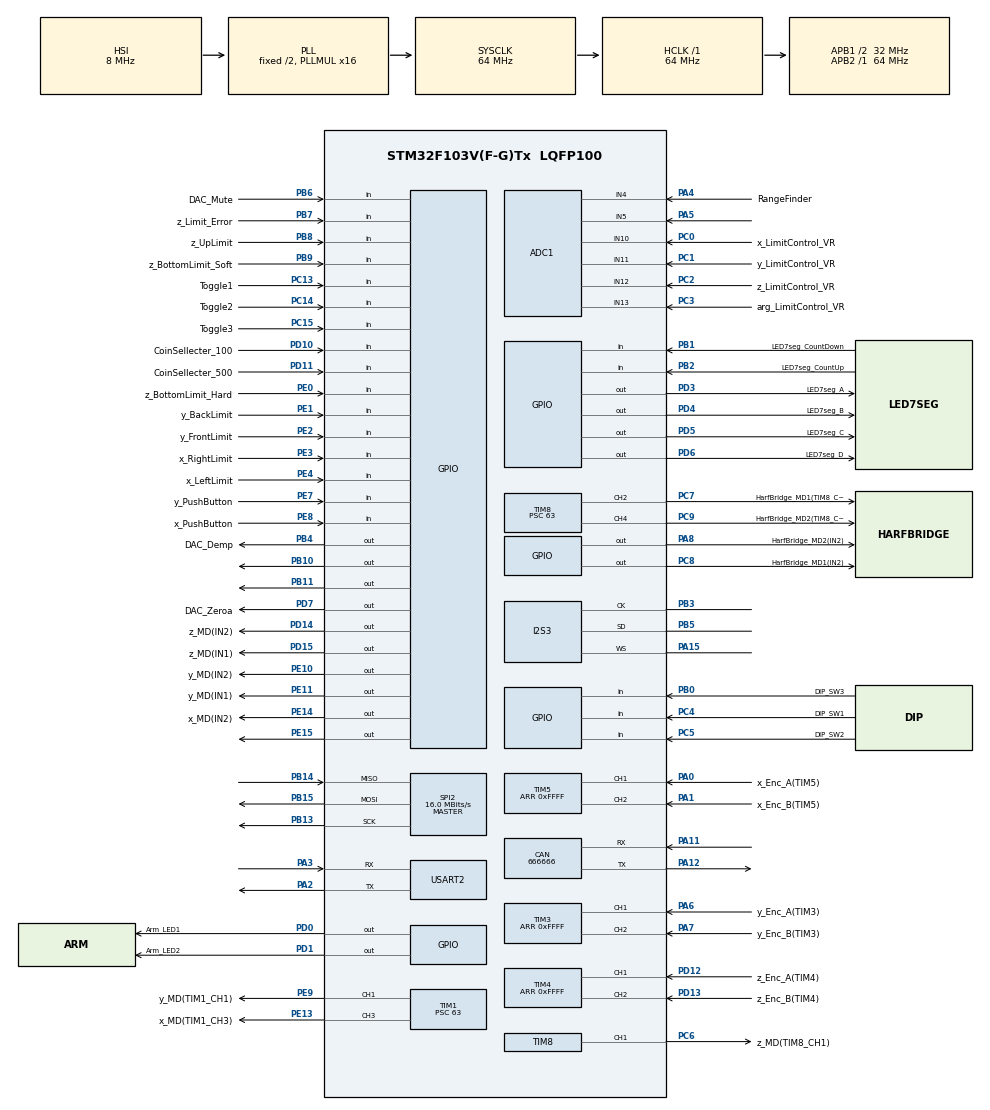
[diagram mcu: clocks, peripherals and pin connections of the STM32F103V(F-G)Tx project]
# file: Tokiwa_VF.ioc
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ADC1.Channel-0\#ChannelRegularConversion=ADC_CHANNEL_10
ADC1.Channel-1\#ChannelRegularConversion=ADC_CHANNEL_11
ADC1.Channel-2\#ChannelRegularConversion=ADC_CHANNEL_12
ADC1.Channel-3\#ChannelRegularConversion=ADC_CHANNEL_13
ADC1.Channel-4\#ChannelRegularConversion=ADC_CHANNEL_5
ADC1.Channel-5\#ChannelRegularConversion=ADC_CHANNEL_4
ADC1.ContinuousConvMode=ENABLE
ADC1.NbrOfConversion=6
ADC1.NbrOfConversionFlag=1
ADC1.Rank-0\#ChannelRegularConversion=1
ADC1.Rank-1\#ChannelRegularConversion=2
ADC1.Rank-2\#ChannelRegularConversion=3
ADC1.Rank-3\#ChannelRegularConversion=4
ADC1.Rank-4\#ChannelRegularConversion=5
ADC1.Rank-5\#ChannelRegularConversion=6
ADC1.SamplingTime-0\#ChannelRegularConversion=ADC_SAMPLETIME_13CYCLES_5
ADC1.SamplingTime-1\#ChannelRegularConversion=ADC_SAMPLETIME_13CYCLES_5
ADC1.SamplingTime-2\#ChannelRegularConversion=ADC_SAMPLETIME_13CYCLES_5
ADC1.SamplingTime-3\#ChannelRegularConversion=ADC_SAMPLETIME_13CYCLES_5
ADC1.SamplingTime-4\#ChannelRegularConversion=ADC_SAMPLETIME_13CYCLES_5
ADC1.SamplingTime-5\#ChannelRegularConversion=ADC_SAMPLETIME_13CYCLES_5
ADC1.master=1
CAN.BS1=CAN_BS1_1TQ
CAN.BS2=CAN_BS2_1TQ
CAN.CalculateBaudRate=666666
CAN.CalculateTimeBit=1500.00
CAN.CalculateTimeQuantum=500.0
Dma.ADC1.0.Direction=DMA_PERIPH_TO_MEMORY
Dma.ADC1.0.Instance=DMA1_Channel1
Dma.ADC1.0.MemDataAlignment=DMA_MDATAALIGN_HALFWORD
Dma.ADC1.0.MemInc=DMA_MINC_ENABLE
Dma.ADC1.0.Mode=DMA_CIRCULAR
Dma.ADC1.0.PeriphDataAlignment=DMA_PDATAALIGN_HALFWORD
Dma.ADC1.0.PeriphInc=DMA_PINC_DISABLE
Dma.ADC1.0.Priority=DMA_PRIORITY_LOW
Dma.Request0=ADC1
I2S3.ErrorAudioFreq=0.0 %
I2S3.Instance=SPI$Index
I2S3.RealAudioFreq=8.0 KHz
I2S3.VirtualMode=I2S_MODE_MASTER
Mcu.Family=STM32F1
Mcu.Name=STM32F103V(F-G)Tx
Mcu.Package=LQFP100
NVIC.DMA1_Channel1_IRQn=true\:0\:0\:false\:false\:true\:false\:true
NVIC.PriorityGroup=NVIC_PRIORITYGROUP_4
NVIC.TIM6_IRQn=true\:1\:0\:true\:false\:true\:true\:true
PA0-WKUP.GPIO_Label=x_Enc_A(TIM5)
PA0-WKUP.Signal=S_TIM5_CH1
PA1.GPIO_Label=x_Enc_B(TIM5)
PA1.Signal=S_TIM5_CH2
PA10.Signal=USART1_RX
PA11.Mode=CAN_Activate
PA11.Signal=CAN_RX
PA12.Mode=CAN_Activate
PA12.Signal=CAN_TX
PA13.Signal=SYS_JTMS-SWDIO
PA14.Signal=SYS_JTCK-SWCLK
PA15.Mode=Half_Duplex_Master_TX
PA15.Signal=I2S3_WS
PA2.Mode=Asynchronous
PA2.Signal=USART2_TX
PA3.Mode=Asynchronous
PA3.Signal=USART2_RX
PA4.GPIO_Label=RangeFinder
PA4.Signal=ADCx_IN4
PA5.Signal=ADCx_IN5
PA6.GPIO_Label=y_Enc_A(TIM3)
PA6.Signal=S_TIM3_CH1
PA7.GPIO_Label=y_Enc_B(TIM3)
PA7.Signal=S_TIM3_CH2
PA8.GPIO_Label=HarfBridge_MD2(IN2)
PA8.Signal=GPIO_Output
PA9.Signal=USART1_TX
PB0.GPIO_Label=DIP_SW3
PB0.Signal=GPIO_Input
PB1.GPIO_Label=LED7seg_CountDown
PB1.Signal=GPIO_Input
PB10.GPIO_PuPd=GPIO_PULLDOWN
PB10.Signal=GPIO_Output
PB11.GPIO_PuPd=GPIO_PULLDOWN
PB11.Signal=GPIO_Output
PB13.Mode=Full_Duplex_Master
PB13.Signal=SPI2_SCK
PB14.Mode=Full_Duplex_Master
PB14.Signal=SPI2_MISO
PB15.Mode=Full_Duplex_Master
PB15.Signal=SPI2_MOSI
PB2.GPIO_Label=LED7seg_CountUp
PB2.Signal=GPIO_Input
PB3.Mode=Half_Duplex_Master_TX
PB3.Signal=I2S3_CK
PB4.GPIO_Label=DAC_Demp
PB4.Signal=GPIO_Output
PB5.Mode=Half_Duplex_Master_TX
PB5.Signal=I2S3_SD
PB6.GPIO_Label=DAC_Mute
PB6.Signal=GPIO_Input
PB7.GPIO_Label=z_Limit_Error
PB7.Signal=GPIO_Input
PB8.GPIO_Label=z_UpLimit
PB8.Signal=GPIO_Input
PB9.GPIO_Label=z_BottomLimit_Soft
PB9.Signal=GPIO_Input
PC0.GPIO_Label=x_LimitControl_VR
PC0.Signal=ADCx_IN10
PC1.GPIO_Label=y_LimitControl_VR
PC1.Signal=ADCx_IN11
PC10.Signal=UART4_TX
PC11.Signal=UART4_RX
PC12.Signal=UART5_TX
PC13-TAMPER-RTC.GPIO_Label=Toggle1
PC13-TAMPER-RTC.Signal=GPIO_Input
PC14-OSC32_IN.GPIO_Label=Toggle2
PC14-OSC32_IN.Signal=GPIO_Input
PC15-OSC32_OUT.GPIO_Label=Toggle3
PC15-OSC32_OUT.Signal=GPIO_Input
PC2.GPIO_Label=z_LimitControl_VR
PC2.Signal=ADCx_IN12
PC3.GPIO_Label=arg_LimitControl_VR
PC3.Signal=ADCx_IN13
PC4.GPIO_Label=DIP_SW1
PC4.Signal=GPIO_Input
PC5.GPIO_Label=DIP_SW2
PC5.Signal=GPIO_Input
PC6.GPIO_Label=z_MD(TIM8_CH1)
PC6.Signal=S_TIM8_CH1
PC7.GPIO_Label=HarfBridge_MD1(TIM8_CH2)
PC7.Signal=S_TIM8_CH2
PC8.GPIO_Label=HarfBridge_MD1(IN2)
PC8.Signal=GPIO_Output
PC9.GPIO_Label=HarfBridge_MD2(TIM8_CH4)
PC9.Signal=S_TIM8_CH4
PD0.GPIO_Label=Arm_LED1
PD0.Signal=GPIO_Output
PD1.GPIO_Label=Arm_LED2
PD1.Signal=GPIO_Output
PD10.GPIO_Label=CoinSellecter_100
PD10.GPIO_PuPd=GPIO_PULLDOWN
PD10.Signal=GPIO_Input
PD11.GPIO_Label=CoinSellecter_500
PD11.Signal=GPIO_Input
PD12.GPIO_Label=z_Enc_A(TIM4)
PD12.Signal=S_TIM4_CH1
PD13.GPIO_Label=z_Enc_B(TIM4)
PD13.Signal=S_TIM4_CH2
PD14.GPIO_Label=z_MD(IN2)
PD14.Signal=GPIO_Output
PD15.GPIO_Label=z_MD(IN1)
PD15.Signal=GPIO_Output
PD2.Signal=UART5_RX
PD3.GPIO_Label=LED7seg_A
PD3.Signal=GPIO_Output
PD4.GPIO_Label=LED7seg_B
PD4.Signal=GPIO_Output
PD5.GPIO_Label=LED7seg_C
PD5.Signal=GPIO_Output
PD6.GPIO_Label=LED7seg_D
PD6.Signal=GPIO_Output
PD7.GPIO_Label=DAC_Zeroa
PD7.Signal=GPIO_Output
PD8.Signal=USART3_TX
PD9.Signal=USART3_RX
PE0.GPIO_Label=z_BottomLimit_Hard
PE0.Signal=GPIO_Input
PE1.GPIO_Label=y_BackLimit
PE1.Signal=GPIO_Input
PE10.GPIO_Label=y_MD(IN2)
PE10.Signal=GPIO_Output
PE11.GPIO_Label=y_MD(IN1)
PE11.Signal=GPIO_Output
PE13.GPIO_Label=x_MD(TIM1_CH3)
PE13.Signal=S_TIM1_CH3
PE14.GPIO_Label=x_MD(IN2)
PE14.Signal=GPIO_Output
PE15.Signal=GPIO_Output
PE2.GPIO_Label=y_FrontLimit
PE2.Signal=GPIO_Input
PE3.GPIO_Label=x_RightLimit
PE3.Signal=GPIO_Input
PE4.GPIO_Label=x_LeftLimit
PE4.Signal=GPIO_Input
PE5.Signal=S_TIM9_CH1
PE6.Signal=S_TIM9_CH2
PE7.GPIO_Label=y_PushButton
PE7.Signal=GPIO_Input
PE8.GPIO_Label=x_PushButton
PE8.Signal=GPIO_Input
PE9.GPIO_Label=y_MD(TIM1_CH1)
PE9.Signal=S_TIM1_CH1
ProjectManager.HeapSize=0x200
ProjectManager.StackSize=0x400
ProjectManager.TargetToolchain=STM32CubeIDE
RCC.ADCPresc=RCC_ADCPCLK2_DIV6
RCC.AHBFreq_Value=64000000
RCC.APB1CLKDivider=RCC_HCLK_DIV2
RCC.APB1Freq_Value=32000000
RCC.APB1TimFreq_Value=64000000
RCC.APB2Freq_Value=64000000
RCC.APB2TimFreq_Value=64000000
RCC.HCLKFreq_Value=64000000
RCC.PLLMUL=RCC_PLL_MUL16
RCC.SYSCLKFreq_VALUE=64000000
RCC.SYSCLKSource=RCC_SYSCLKSOURCE_PLLCLK
RCC.USBFreq_Value=64000000
SH.ADCx_IN10.0=ADC1_IN10,IN10
SH.ADCx_IN11.0=ADC1_IN11,IN11
SH.ADCx_IN12.0=ADC1_IN12,IN12
SH.ADCx_IN13.0=ADC1_IN13,IN13
SH.ADCx_IN4.0=ADC1_IN4,IN4
SH.ADCx_IN5.0=ADC1_IN5,IN5
SH.S_TIM1_CH1.0=TIM1_CH1,PWM Generation1 CH1
SH.S_TIM1_CH3.0=TIM1_CH3,PWM Generation3 CH3
SH.S_TIM3_CH1.0=TIM3_CH1,Encoder_Interface
SH.S_TIM3_CH2.0=TIM3_CH2,Encoder_Interface
SH.S_TIM4_CH1.0=TIM4_CH1,Encoder_Interface
SH.S_TIM4_CH2.0=TIM4_CH2,Encoder_Interface
SH.S_TIM5_CH1.0=TIM5_CH1,Encoder_Interface
SH.S_TIM5_CH2.0=TIM5_CH2,Encoder_Interface
SH.S_TIM8_CH1.0=TIM8_CH1,PWM Generation1 CH1
SH.S_TIM8_CH2.0=TIM8_CH2,PWM Generation2 CH2
SH.S_TIM8_CH4.0=TIM8_CH4,PWM Generation4 CH4
SH.S_TIM9_CH1.0=TIM9_CH1
SH.S_TIM9_CH2.0=TIM9_CH2
SPI2.BaudRatePrescaler=SPI_BAUDRATEPRESCALER_2
SPI2.CalculateBaudRate=16.0 MBits/s
SPI2.Direction=SPI_DIRECTION_2LINES
SPI2.Mode=SPI_MODE_MASTER
SPI2.VirtualType=VM_MASTER
TIM1.Channel-PWM\ Generation1\ CH1=TIM_CHANNEL_1
TIM1.Channel-PWM\ Generation3\ CH3=TIM_CHANNEL_3
TIM1.Period=99
TIM1.Prescaler=63
TIM2.Period=99
TIM2.Prescaler=31
TIM3.EncoderMode=TIM_ENCODERMODE_TI12
TIM3.IC1Prescaler=TIM_ICPSC_DIV1
TIM3.IC2Prescaler=TIM_ICPSC_DIV1
TIM3.Period=0xFFFF
TIM4.EncoderMode=TIM_ENCODERMODE_TI12
TIM4.Period=0xFFFF
TIM5.EncoderMode=TIM_ENCODERMODE_TI12
TIM5.Period=0xFFFF
TIM6.Period=99
TIM6.Prescaler=6399
TIM8.Channel-PWM\ Generation1\ CH1=TIM_CHANNEL_1
TIM8.Channel-PWM\ Generation2\ CH2=TIM_CHANNEL_2
TIM8.Channel-PWM\ Generation4\ CH4=TIM_CHANNEL_4
TIM8.Period=99
TIM8.Prescaler=63
USART2.VirtualMode=VM_ASYNC
VP_SYS_VS_ND.Mode=No_Debug
VP_TIM2_VS_OPM.Mode=OPM_bit
VP_TIM6_VS_ClockSourceINT.Mode=Enable_Timer
board=custom

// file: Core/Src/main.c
/* USER CODE BEGIN Header */
/**
  ******************************************************************************
  * @file           : main.c
  * @brief          : Main program body
  ******************************************************************************
  * @attention
  *
  * <h2><center>&copy; Copyright (c) 2019 STMicroelectronics.
  * All rights reserved.</center></h2>
  *
  * This software component is licensed by ST under BSD 3-Clause license,
  * the "License"; You may not use this file except in compliance with the
  * License. You may obtain a copy of the License at:
  *                        opensource.org/licenses/BSD-3-Clause
  *
  ******************************************************************************
  */
/* USER CODE END Header */
#include "main.h"
#include "adc.h"
#include "can.h"
#include "dma.h"
#include "i2s.h"
#include "spi.h"
#include "tim.h"
#include "usart.h"
#include "gpio.h"

/* USER CODE BEGIN Includes */
#include "buttons.h"
#include "limitswitches.h"
#include "toggleswitches.h"
#include "dipswitches.h"
#include "encoder.h"
#include "led7seg.h"
#include "motor.h"
#include <math.h>
#include <stdio.h>

/* USER CODE END Includes */

/* USER CODE BEGIN PM */
#define X_ENC_LIMIT (77680)
#define Y_ENC_LIMIT (58000) // マイナス
#define Z_ENC_LIMIT (160000) // マイナス

/* USER CODE END PM */

/* USER CODE BEGIN PV */
static uint16_t adcbuff[6]; // 0~2:xyzLimit 3:XY速度 4:開閉速度 6番目はRangeFinder
static uint8_t count = 0;
static int32_t x_enc = 0, y_enc = 0, z_enc = 0;
/* USER CODE END PV */

void SystemClock_Config(void);
/* USER CODE BEGIN PFP */
void Rot90deg_Stepper(float rpm);
void Update_Enc(void);
/* USER CODE END PFP */

int main(void)
{

  /* MCU Configuration--------------------------------------------------------*/

  /* Reset of all peripherals, Initializes the Flash interface and the Systick. */
  HAL_Init();

  /* Configure the system clock */
  SystemClock_Config();

  /* Initialize all configured peripherals */
  MX_GPIO_Init();
  MX_DMA_Init();
  MX_ADC1_Init();
  MX_CAN_Init();
  MX_I2S3_Init();
  MX_SPI2_Init();
  MX_TIM1_Init();
  MX_TIM2_Init();
  MX_TIM3_Init();
  MX_TIM4_Init();
  MX_TIM5_Init();
  MX_TIM8_Init();
  MX_USART2_UART_Init();
  MX_TIM6_Init();
  /* USER CODE BEGIN 2 */
  HAL_UART_Transmit(&huart2, "START\r\n", 7, 0xFFFF);
  HAL_TIM_Encoder_Start(&htim3, TIM_CHANNEL_ALL);
  HAL_TIM_Encoder_Start(&htim4, TIM_CHANNEL_ALL);
  HAL_TIM_Encoder_Start(&htim5, TIM_CHANNEL_ALL);

  HAL_GPIO_WritePin(Arm_LED1_GPIO_Port, Arm_LED1_Pin, GPIO_PIN_SET);
  HAL_GPIO_WritePin(Arm_LED2_GPIO_Port, Arm_LED2_Pin, GPIO_PIN_SET);

  HAL_TIM_PWM_Start(&htim1, TIM_CHANNEL_3);
  HAL_TIM_PWM_Start(&htim1, TIM_CHANNEL_1);
  HAL_TIM_PWM_Start(&htim8, TIM_CHANNEL_1);

  Display_led7seg(count);

  /* ADCサンプリング･DMA転送開始 */
  HAL_ADC_Start_DMA(&hadc1, adcbuff, 6);

//  while (1) {
//      uint8_t buff[40];
//      HAL_ADC_Start_DMA(&hadc1, adcbuff, 6);
//      sprintf(buff, "%4d %4d %4d %4d %4d %4d ", adcbuff[0], adcbuff[1], adcbuff[2], adcbuff[3], adcbuff[4], adcbuff[5]);
//      HAL_UART_Transmit(&huart2, buff, 30, 0xFFFF); // 各ADCの値
//      sprintf(buff, "x%6d y%6d z%6d\r\n", x_enc, y_enc, z_enc);
//      HAL_UART_Transmit(&huart2, buff, 25, 0xFFFF); // 各encの値
////      Display_led7seg(10);
////      HAL_Delay(5);
////      Display_led7seg(13);
////      HAL_Delay(5);
//      Update_Enc();
//  }

  /* タイマ割り込み開始 */
  HAL_TIM_Base_Start_IT(&htim6);
  /* USER CODE END 2 */

  /* Infinite loop */
  while (1)
  {

    /* USER CODE BEGIN 3 */
	  /* テスト用 */
	  uint8_t buff[40];
//	  sprintf(buff, "%4d %4d %4d %4d %4d\r\n", adcbuff[0], adcbuff[1], adcbuff[2], adcbuff[3], adcbuff[4]);
//	  HAL_UART_Transmit(&huart2, buff, 26, 0xFFFF); // 各ADCの値
	  sprintf(buff, "x%6d y%6d z%7d\r\n", x_enc,
	                                         y_enc,
	                                         z_enc);
	  HAL_UART_Transmit(&huart2, buff, 26, 0xFFFF); // 各encの値
//	  sprintf(buff, "xL%6d yL%6d zL%7d\r\n", (int)(X_ENC_LIMIT / 4095.0 * adcbuff[0]),
//	                                         (int)(Y_ENC_LIMIT / 4095.0 * adcbuff[1]),
//	                                         (int)(Z_ENC_LIMIT / 4095.0 * adcbuff[2]));
//	  HAL_UART_Transmit(&huart2, buff, 29, 0xFFFF); // 各encの値
      if (x_enc >= X_ENC_LIMIT * (adcbuff[0] / 4095.0f)) {
          HAL_UART_Transmit(&huart2, "A\r\n", 3, 0xFFFF); // 各encの値
      }
//	  if(isPressed_x_LeftLimit())
//		  HAL_UART_Transmit(&huart2, "xL", 2, 0xFFFF);
//	  if(isPressed_x_RightLimit())
//		  HAL_UART_Transmit(&huart2, "xR", 2, 0xFFFF);
//	  if(isPressed_y_BackLimit())
//		  HAL_UART_Transmit(&huart2, "yB", 2, 0xFFFF);
//	  if(isPressed_y_FrontLimit())
//		  HAL_UART_Transmit(&huart2, "yF", 2, 0xFFFF);
//	  if(isPressed_z_UpLimit())
//		  HAL_UART_Transmit(&huart2, "zU", 2, 0xFFFF);
//	  if(isPressed_z_Limit_Error())
//		  HAL_UART_Transmit(&huart2, "zE", 2, 0xFFFF);
//	  if(isPressed_z_BottomLimit_Hard())
//		  HAL_UART_Transmit(&huart2, "zBH", 3, 0xFFFF);
//	  if(isPressed_z_BottomLimit_Soft())
//		  HAL_UART_Transmit(&huart2, "zBS", 3, 0xFFFF);
//	  if(isPressed_x_PushButton())
//		  HAL_UART_Transmit(&huart2, "xP", 2, 0xFFFF);
//	  if(isPressed_y_PushButton())
//		  HAL_UART_Transmit(&huart2, "yP", 2, 0xFFFF);
//	  if(isHigh_DIP_SW1())
//		  HAL_UART_Transmit(&huart2, "D1", 2, 0xFFFF);
//	  if(isHigh_DIP_SW2())
//		  HAL_UART_Transmit(&huart2, "D2", 2, 0xFFFF);
//	  if(isHigh_DIP_SW3())
//		  HAL_UART_Transmit(&huart2, "D3", 2, 0xFFFF);
//	  if(isHigh_Toggle1())
//		  HAL_UART_Transmit(&huart2, "T1", 2, 0xFFFF);
//	  if(isHigh_Toggle2())
//		  HAL_UART_Transmit(&huart2, "T2", 2, 0xFFFF);
//	  if(isHigh_Toggle3())
//		  HAL_UART_Transmit(&huart2, "T3", 2, 0xFFFF);

  }
  /* USER CODE END 3 */
}

void SystemClock_Config(void)
{
  RCC_OscInitTypeDef RCC_OscInitStruct = {0};
  RCC_ClkInitTypeDef RCC_ClkInitStruct = {0};
  RCC_PeriphCLKInitTypeDef PeriphClkInit = {0};

  /** Initializes the RCC Oscillators according to the specified parameters
  * in the RCC_OscInitTypeDef structure.
  */
  RCC_OscInitStruct.OscillatorType = RCC_OSCILLATORTYPE_HSI;
  RCC_OscInitStruct.HSIState = RCC_HSI_ON;
  RCC_OscInitStruct.HSICalibrationValue = RCC_HSICALIBRATION_DEFAULT;
  RCC_OscInitStruct.PLL.PLLState = RCC_PLL_ON;
  RCC_OscInitStruct.PLL.PLLSource = RCC_PLLSOURCE_HSI_DIV2;
  RCC_OscInitStruct.PLL.PLLMUL = RCC_PLL_MUL16;
  if (HAL_RCC_OscConfig(&RCC_OscInitStruct) != HAL_OK)
  {
    Error_Handler();
  }
  /** Initializes the CPU, AHB and APB buses clocks
  */
  RCC_ClkInitStruct.ClockType = RCC_CLOCKTYPE_HCLK|RCC_CLOCKTYPE_SYSCLK
                              |RCC_CLOCKTYPE_PCLK1|RCC_CLOCKTYPE_PCLK2;
  RCC_ClkInitStruct.SYSCLKSource = RCC_SYSCLKSOURCE_PLLCLK;
  RCC_ClkInitStruct.AHBCLKDivider = RCC_SYSCLK_DIV1;
  RCC_ClkInitStruct.APB1CLKDivider = RCC_HCLK_DIV2;
  RCC_ClkInitStruct.APB2CLKDivider = RCC_HCLK_DIV1;

  if (HAL_RCC_ClockConfig(&RCC_ClkInitStruct, FLASH_LATENCY_2) != HAL_OK)
  {
    Error_Handler();
  }
  PeriphClkInit.PeriphClockSelection = RCC_PERIPHCLK_ADC|RCC_PERIPHCLK_I2S3;
  PeriphClkInit.AdcClockSelection = RCC_ADCPCLK2_DIV6;
  PeriphClkInit.I2s3ClockSelection = RCC_I2S3CLKSOURCE_SYSCLK;
  if (HAL_RCCEx_PeriphCLKConfig(&PeriphClkInit) != HAL_OK)
  {
    Error_Handler();
  }
}

/* USER CODE BEGIN 4 */
// Yプラスで手前
// Xプラスで右
// Zプラスで上
// タイマ割り込み処理 TIM6を使用 100Hzか50Hzのはず
enum phase { WAIT_X, MOVE_X, WAIT_Y, MOVE_Y, WAIT_OPEN, OPEN, WAIT_DOWN, DOWN,
    WAIT_PICK, PICK, WAIT_UP, UP, WAIT_MOVE3, MOVE3, RELEASE, WAIT_CLOSE, CLOSE, WAIT_FINAL};
static uint8_t phase = WAIT_X;
static uint32_t frame_cnt = 0;
static uint32_t timeCount = 0;
static bool isnotreset_coin = false; // コインの連続投入をカウントするために、一度コインが離れるまでtrue
void HAL_TIM_PeriodElapsedCallback(TIM_HandleTypeDef *htim)
{
    if (htim == &htim6)
    {
        Update_Enc();
//        if (isPressed_z_Limit_Error()) { // TODO:
//            // エラー時 停止
//            Set_Motor_X(0);
//            Set_Motor_Y(0);
//            Set_Motor_Z(0);
//            Set_Motor_Half_1(0);
//            Set_Motor_Half_2(0);
//            while(1);
//        }

        if (phase == WAIT_X) {
            if (frame_cnt > 0) { // 何もしない
                if (!isPressed_LED7seg_CountUP() && !isPressed_LED7seg_CountDown()) {
                    frame_cnt = 0;
                }
            }
            else if (isPressed_LED7seg_CountUP() || isPressed_CoinSelecter_100()) {
                frame_cnt++; // オーバーフローしそう
                if (count < 9) {
                    count++;
                }
            }
            else if (isPressed_LED7seg_CountDown()) {
                frame_cnt++;
                count--;
            }

            // 残りプレイ回数を表示
            Display_led7seg(count);

            if (count > 0 && isPressed_x_PushButton()) {
                phase = MOVE_X;
                frame_cnt = 0;
            }
        }
        else if (phase == MOVE_X) {
            Set_Motor_X(80 * (adcbuff[3] / 4095.0f) + 1); // Xプラスで右
            if (isPressed_x_RightLimit() || x_enc >= X_ENC_LIMIT / 4095.0 * adcbuff[0] || !isPressed_x_PushButton()) {
                Set_Motor_X(0);
                phase = WAIT_Y;
            }
        }
        else if (phase == WAIT_Y) {
            if (isPressed_y_PushButton()) {
                phase = MOVE_Y;
            }
        }
        else if (phase == MOVE_Y) {
            Set_Motor_Y(-80 * (adcbuff[3] / 4095.0f) - 1); // Yプラスで手前
            if (isPressed_y_BackLimit() || y_enc <= -Y_ENC_LIMIT / 4095.0 * adcbuff[1] || !isPressed_y_PushButton()) {
                Set_Motor_Y(0);
                phase = WAIT_OPEN;
            }
        }
        else if (phase == WAIT_OPEN) {
            // ただの時間待ち
            timeCount++;
            if (timeCount > 100) {
                timeCount = 0;
                phase = OPEN;
            }
        }
        else if (phase == OPEN) {
            // アーム開く
            Rot90deg_Stepper(80 * (adcbuff[4] / 4095.0f) + 1);
            phase = WAIT_DOWN;
        }
        else if (phase == WAIT_DOWN) {
            // ただの時間待ち
            timeCount++;
            if (timeCount > 100) {
                timeCount = 0;
                phase = DOWN;
            }
        }
        else if (phase == DOWN) {
            Set_Motor_Z(-100);
            if (isPressed_z_BottomLimit_Soft() || z_enc <= -Z_ENC_LIMIT * adcbuff[2] / 4095.0) {
                Set_Motor_Z(0);
                phase = WAIT_PICK;
            }
        }
        else if (phase == WAIT_PICK) {
            // ただの時間待ち
            timeCount++;
            if (timeCount > 200) {
                timeCount = 0;
                phase = PICK;
            }
        }
        else if (phase == PICK) {
            // アーム閉じる
            Rot90deg_Stepper(80 * (adcbuff[4] / 4095.0f) + 1);
            phase = WAIT_UP;
        }
        else if (phase == WAIT_UP) {
            // ただの時間待ち
            timeCount++;
            if (timeCount > 100) {
                timeCount = 0;
                phase = UP;
            }
        }
        else if (phase == UP) {
            Set_Motor_Z(100);

            if (isPressed_z_UpLimit()) { //TODO:
                Set_Motor_Z(0);
                timeCount = 0;
                phase = WAIT_MOVE3;
            }

//            timeCount++;
//            if (timeCount > 400) { // TODO:今は時間待ちになっている
//                Set_Motor_Z(0);
//                timeCount = 0;
//                phase = WAIT_MOVE3;
//            }
//                phase = WAIT_MOVE3;
//            }
        }
        else if (phase == WAIT_MOVE3) {
            // ただの時間待ち
            timeCount++;
            if (timeCount > 100) {
                timeCount = 0;
                phase = MOVE3;
            }
        }
        else if (phase == MOVE3) {
            if (isPressed_y_FrontLimit()) {
                Set_Motor_Y(0);
            }
            else {
                Set_Motor_Y(80 * (adcbuff[3] / 4095.0f) + 1);
            }
            if (isPressed_x_LeftLimit()) {
                Set_Motor_X(0);
            }
            else {
                Set_Motor_X(-80 * (adcbuff[3] / 4095.0f) - 1);
            }

            if (isPressed_y_FrontLimit() && isPressed_x_LeftLimit()) {
                // モーター止める
                Set_Motor_X(0);
                Set_Motor_Y(0);
                // 待つ
                timeCount++;
                if (timeCount > 100) {
                    timeCount = 0;
                    count--;
                    phase = RELEASE;
                }
            }
        }
        else if (phase == RELEASE) {
            // アーム開く
            Rot90deg_Stepper(80 * (adcbuff[4] / 4095.0f) + 1);
            phase = CLOSE;
        }
        else if(phase == WAIT_CLOSE) {
            timeCount++;
            if (timeCount > 200) {
                timeCount = 0;
                phase = CLOSE;//162422
            }
        }
        else if (phase == CLOSE) {
            // アーム閉じる
            Rot90deg_Stepper(80 * (adcbuff[4] / 4095.0f) + 1);
            phase = WAIT_FINAL;
        }
        else if (phase == WAIT_FINAL) {
            timeCount++;
            if (timeCount > 200) {
                timeCount = 0;
                phase = WAIT_X; // 最初に戻る
            }
        }
    }
}

#define STEP_DEG (7.5)
void Rot90deg_Stepper(float rpm) {
    uint32_t delay_ms = 60000 / (360 / STEP_DEG) / 4 / rpm;
    for (uint32_t i = 0; i < 12*7.5; i++) {
        HAL_GPIO_WritePin(GPIOB, GPIO_PIN_10, GPIO_PIN_RESET);
        HAL_GPIO_WritePin(GPIOB, GPIO_PIN_11, GPIO_PIN_RESET);
        HAL_Delay(delay_ms);
        HAL_GPIO_WritePin(GPIOB, GPIO_PIN_10, GPIO_PIN_RESET);
        HAL_GPIO_WritePin(GPIOB, GPIO_PIN_11, GPIO_PIN_SET);
        HAL_Delay(delay_ms);
        HAL_GPIO_WritePin(GPIOB, GPIO_PIN_10, GPIO_PIN_SET);
        HAL_GPIO_WritePin(GPIOB, GPIO_PIN_11, GPIO_PIN_SET);
        HAL_Delay(delay_ms);
        HAL_GPIO_WritePin(GPIOB, GPIO_PIN_10, GPIO_PIN_SET);
        HAL_GPIO_WritePin(GPIOB, GPIO_PIN_11, GPIO_PIN_RESET);
        HAL_Delay(delay_ms);
    }
    HAL_GPIO_WritePin(GPIOB, GPIO_PIN_10, GPIO_PIN_RESET);
    HAL_GPIO_WritePin(GPIOB, GPIO_PIN_11, GPIO_PIN_RESET);
}

void Update_Enc(void) {
    if (isPressed_x_LeftLimit()) {
        x_enc = 0;
        Set_x_Enc(0);
    }
    else if (isPressed_x_RightLimit()) {
        x_enc = X_ENC_LIMIT;
        Set_x_Enc(0);
    }
    else {
        x_enc += Get_x_Enc();
        Set_x_Enc(0);
    }

    if (isPressed_y_FrontLimit()) {
        y_enc = 0;
        Set_y_Enc(0);
    }
    else if (isPressed_y_BackLimit()) {
        y_enc = -Y_ENC_LIMIT;
        Set_y_Enc(0);
    }
    else {
        y_enc += Get_y_Enc();
        Set_y_Enc(0);
    }

    if (isPressed_z_UpLimit()) {
        z_enc = 0;
        Set_z_Enc(0);
    }
//    else if (isPressed_z_UpLimit()) {
//
//    }
    else {
        z_enc += Get_z_Enc();
        Set_z_Enc(0);
    }
}

/* USER CODE END 4 */

void Error_Handler(void)
{
}

/************************ (C) COPYRIGHT STMicroelectronics *****END OF FILE****/
